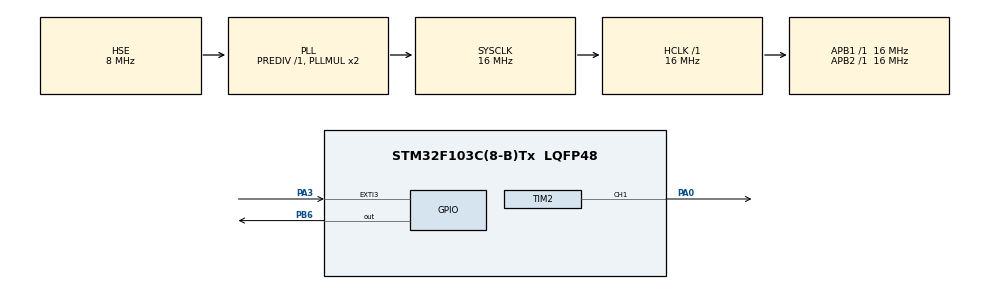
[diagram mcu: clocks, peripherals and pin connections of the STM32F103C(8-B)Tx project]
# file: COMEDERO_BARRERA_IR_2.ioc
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Mcu.Family=STM32F1
Mcu.Name=STM32F103C(8-B)Tx
Mcu.Package=LQFP48
NVIC.EXTI3_IRQn=true\:0\:0\:false\:false\:true\:true\:true\:true
NVIC.PriorityGroup=NVIC_PRIORITYGROUP_4
PA0-WKUP.Signal=S_TIM2_CH1_ETR
PA13.Mode=Serial_Wire
PA13.Signal=SYS_JTMS-SWDIO
PA14.Mode=Serial_Wire
PA14.Signal=SYS_JTCK-SWCLK
PA3.Signal=GPXTI3
PB6.Signal=GPIO_Output
PD0-OSC_IN.Mode=HSE-External-Oscillator
PD0-OSC_IN.Signal=RCC_OSC_IN
PD1-OSC_OUT.Mode=HSE-External-Oscillator
PD1-OSC_OUT.Signal=RCC_OSC_OUT
ProjectManager.HeapSize=0x200
ProjectManager.StackSize=0x400
ProjectManager.TargetToolchain=STM32CubeIDE
RCC.AHBFreq_Value=16000000
RCC.APB1Freq_Value=16000000
RCC.APB1TimFreq_Value=16000000
RCC.APB2Freq_Value=16000000
RCC.APB2TimFreq_Value=16000000
RCC.HCLKFreq_Value=16000000
RCC.PLLSourceVirtual=RCC_PLLSOURCE_HSE
RCC.SYSCLKFreq_VALUE=16000000
RCC.SYSCLKSource=RCC_SYSCLKSOURCE_PLLCLK
RCC.USBFreq_Value=16000000
SH.S_TIM2_CH1_ETR.0=TIM2_CH1,PWM Generation1 CH1
TIM2.Channel-PWM\ Generation1\ CH1=TIM_CHANNEL_1
VP_TIM2_VS_ClockSourceINT.Mode=Internal
VP_TIM3_VS_ClockSourceINT.Mode=Internal
board=custom

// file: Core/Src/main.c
/* USER CODE BEGIN Header */
/**
  ******************************************************************************
  * @file           : main.c
  * @brief          : Main program body
  ******************************************************************************
  * @attention
  *
  * Copyright (c) 2025 STMicroelectronics.
  * All rights reserved.
  *
  * This software is licensed under terms that can be found in the LICENSE file
  * in the root directory of this software component.
  * If no LICENSE file comes with this software, it is provided AS-IS.
  *
  ******************************************************************************
  */
/* USER CODE END Header */
#include "main.h"

TIM_HandleTypeDef htim2;
TIM_HandleTypeDef htim3;

/* USER CODE BEGIN PV */
volatile uint32_t ir_count = 0;
/* USER CODE END PV */

void SystemClock_Config(void);
static void MX_GPIO_Init(void);
static void MX_TIM2_Init(void);
static void MX_TIM3_Init(void);
/* USER CODE BEGIN PFP */
void delay_us(uint32_t us);
int readBarrier(unsigned int len);
/* USER CODE END PFP */

int main(void)
{

  /* MCU Configuration--------------------------------------------------------*/

  /* Reset of all peripherals, Initializes the Flash interface and the Systick. */
  HAL_Init();

  /* Configure the system clock */
  SystemClock_Config();

  /* Initialize all configured peripherals */
  MX_GPIO_Init();
  MX_TIM3_Init();
  MX_TIM2_Init();

  /* Infinite loop */
  /* USER CODE BEGIN WHILE */
  while (1)
  {
	  int c = readBarrier(10);

	  if(c > 0){
		  HAL_GPIO_WritePin(GPIOB, GPIO_PIN_6, GPIO_PIN_SET);
	  }else{
		  HAL_GPIO_WritePin(GPIOB, GPIO_PIN_6, GPIO_PIN_RESET);
	  }
    /* USER CODE END WHILE */

  }
}

void SystemClock_Config(void)
{
  RCC_OscInitTypeDef RCC_OscInitStruct = {0};
  RCC_ClkInitTypeDef RCC_ClkInitStruct = {0};

  /** Initializes the RCC Oscillators according to the specified parameters
  * in the RCC_OscInitTypeDef structure.
  */
  RCC_OscInitStruct.OscillatorType = RCC_OSCILLATORTYPE_HSE;
  RCC_OscInitStruct.HSEState = RCC_HSE_ON;
  RCC_OscInitStruct.HSEPredivValue = RCC_HSE_PREDIV_DIV1;
  RCC_OscInitStruct.HSIState = RCC_HSI_ON;
  RCC_OscInitStruct.PLL.PLLState = RCC_PLL_ON;
  RCC_OscInitStruct.PLL.PLLSource = RCC_PLLSOURCE_HSE;
  RCC_OscInitStruct.PLL.PLLMUL = RCC_PLL_MUL2;
  if (HAL_RCC_OscConfig(&RCC_OscInitStruct) != HAL_OK)
  {
    Error_Handler();
  }

  /** Initializes the CPU, AHB and APB buses clocks
  */
  RCC_ClkInitStruct.ClockType = RCC_CLOCKTYPE_HCLK|RCC_CLOCKTYPE_SYSCLK
                              |RCC_CLOCKTYPE_PCLK1|RCC_CLOCKTYPE_PCLK2;
  RCC_ClkInitStruct.SYSCLKSource = RCC_SYSCLKSOURCE_PLLCLK;
  RCC_ClkInitStruct.AHBCLKDivider = RCC_SYSCLK_DIV1;
  RCC_ClkInitStruct.APB1CLKDivider = RCC_HCLK_DIV1;
  RCC_ClkInitStruct.APB2CLKDivider = RCC_HCLK_DIV1;

  if (HAL_RCC_ClockConfig(&RCC_ClkInitStruct, FLASH_LATENCY_0) != HAL_OK)
  {
    Error_Handler();
  }
}

static void MX_TIM2_Init(void)
{

  TIM_ClockConfigTypeDef sClockSourceConfig = {0};
  TIM_MasterConfigTypeDef sMasterConfig = {0};
  TIM_OC_InitTypeDef sConfigOC = {0};

  /* USER CODE BEGIN TIM2_Init 1 */

  uint32_t pclk1 = HAL_RCC_GetPCLK1Freq();
  uint32_t timer_clk = pclk1;
  if(pclk1 != SystemCoreClock)
  {
	  timer_clk = pclk1 * 2;
  }

  const uint32_t target_freq = 38000UL;
  uint32_t period = (timer_clk / target_freq);
  if(period == 0) period = 1;
  period = period - 1;

  /* USER CODE END TIM2_Init 1 */
  htim2.Instance = TIM2;
  htim2.Init.Prescaler = 0;
  htim2.Init.CounterMode = TIM_COUNTERMODE_UP;
  htim2.Init.Period = period;
  htim2.Init.ClockDivision = TIM_CLOCKDIVISION_DIV1;
  htim2.Init.AutoReloadPreload = TIM_AUTORELOAD_PRELOAD_DISABLE;
  if (HAL_TIM_Base_Init(&htim2) != HAL_OK)
  {
    Error_Handler();
  }
  sClockSourceConfig.ClockSource = TIM_CLOCKSOURCE_INTERNAL;
  if (HAL_TIM_ConfigClockSource(&htim2, &sClockSourceConfig) != HAL_OK)
  {
    Error_Handler();
  }
  if (HAL_TIM_PWM_Init(&htim2) != HAL_OK)
  {
    Error_Handler();
  }
  sMasterConfig.MasterOutputTrigger = TIM_TRGO_RESET;
  sMasterConfig.MasterSlaveMode = TIM_MASTERSLAVEMODE_DISABLE;
  if (HAL_TIMEx_MasterConfigSynchronization(&htim2, &sMasterConfig) != HAL_OK)
  {
    Error_Handler();
  }
  sConfigOC.OCMode = TIM_OCMODE_PWM1;
  sConfigOC.Pulse = (htim2.Init.Period + 1) / 2;
  sConfigOC.OCPolarity = TIM_OCPOLARITY_HIGH;
  sConfigOC.OCFastMode = TIM_OCFAST_DISABLE;
  if (HAL_TIM_PWM_ConfigChannel(&htim2, &sConfigOC, TIM_CHANNEL_1) != HAL_OK)
  {
    Error_Handler();
  }
  /* USER CODE BEGIN TIM2_Init 2 */
  GPIO_InitTypeDef GPIO_InitStruct = {0};
  __HAL_RCC_GPIOA_CLK_ENABLE();
  GPIO_InitStruct.Pin = GPIO_PIN_0;
  GPIO_InitStruct.Mode = GPIO_MODE_AF_PP;
  GPIO_InitStruct.Speed = GPIO_SPEED_FREQ_HIGH;
  HAL_GPIO_Init(GPIOA, &GPIO_InitStruct);
  /* USER CODE END TIM2_Init 2 */
  HAL_TIM_MspPostInit(&htim2);

}

static void MX_TIM3_Init(void)
{

  TIM_ClockConfigTypeDef sClockSourceConfig = {0};
  TIM_MasterConfigTypeDef sMasterConfig = {0};

  /* USER CODE BEGIN TIM3_Init 1 */
  uint32_t pclk1 = HAL_RCC_GetPCLK1Freq();
      uint32_t tim_clk = pclk1;
      if (HAL_RCC_GetHCLKFreq() != pclk1) {
          /* If APB1 prescaler != 1 the timer clock is PCLK1 * 2 */
          tim_clk = pclk1 * 2;
      }

      uint32_t presc = (tim_clk / 1000000UL);
      if (presc == 0) presc = 1;
      presc = presc - 1; /* prescaler register = division - 1 */

  /* USER CODE END TIM3_Init 1 */
  htim3.Instance = TIM3;
  htim3.Init.Prescaler = presc;
  htim3.Init.CounterMode = TIM_COUNTERMODE_UP;
  htim3.Init.Period = 0xFFFF;
  htim3.Init.ClockDivision = TIM_CLOCKDIVISION_DIV1;
  htim3.Init.AutoReloadPreload = TIM_AUTORELOAD_PRELOAD_DISABLE;
  if (HAL_TIM_Base_Init(&htim3) != HAL_OK)
  {
    Error_Handler();
  }
  sClockSourceConfig.ClockSource = TIM_CLOCKSOURCE_INTERNAL;
  if (HAL_TIM_ConfigClockSource(&htim3, &sClockSourceConfig) != HAL_OK)
  {
    Error_Handler();
  }
  sMasterConfig.MasterOutputTrigger = TIM_TRGO_RESET;
  sMasterConfig.MasterSlaveMode = TIM_MASTERSLAVEMODE_DISABLE;
  if (HAL_TIMEx_MasterConfigSynchronization(&htim3, &sMasterConfig) != HAL_OK)
  {
    Error_Handler();
  }

}

static void MX_GPIO_Init(void)
{
  GPIO_InitTypeDef GPIO_InitStruct = {0};

  /* GPIO Ports Clock Enable */
  __HAL_RCC_GPIOD_CLK_ENABLE();
  //__HAL_RCC_GPIOA_CLK_ENABLE();
  __HAL_RCC_GPIOB_CLK_ENABLE();

  /*Configure GPIO pin Output Level */
  HAL_GPIO_WritePin(GPIOB, GPIO_PIN_6, GPIO_PIN_RESET);

  /*Configure GPIO pin : PA3 */
  GPIO_InitStruct.Pin = GPIO_PIN_3;
  GPIO_InitStruct.Mode = GPIO_MODE_IT_RISING;
  GPIO_InitStruct.Pull = GPIO_NOPULL;
  HAL_GPIO_Init(GPIOA, &GPIO_InitStruct);

  /*Configure GPIO pin : PB6 */
  GPIO_InitStruct.Pin = GPIO_PIN_6;
  GPIO_InitStruct.Mode = GPIO_MODE_OUTPUT_PP;
  GPIO_InitStruct.Pull = GPIO_NOPULL;
  GPIO_InitStruct.Speed = GPIO_SPEED_FREQ_LOW;
  HAL_GPIO_Init(GPIOB, &GPIO_InitStruct);

  /* EXTI interrupt init*/
  HAL_NVIC_SetPriority(EXTI3_IRQn, 0, 0);
  HAL_NVIC_EnableIRQ(EXTI3_IRQn);

}

/* USER CODE BEGIN 4 */

int readBarrier(unsigned int len)
{
	for(unsigned int i = 0; i < len; i ++)
	{
		HAL_TIM_PWM_Start(&htim2, TIM_CHANNEL_1);
		delay_us(600);
		HAL_TIM_PWM_Stop(&htim2, TIM_CHANNEL_1);
		delay_us(900);
	}

	uint32_t cnt = ir_count;
	ir_count = 0;
	HAL_Delay(22); // min pause.
	return (int)cnt;
}

void delay_us(uint32_t us)
{
    uint32_t start = __HAL_TIM_GET_COUNTER(&htim3);
    /* if timer stopped / not running, avoid infinite loop */
    uint32_t timeout = us + 1000;
    while ((__HAL_TIM_GET_COUNTER(&htim3) - start) < us)
    {
        if (--timeout == 0) break;
    }
}

void HAL_GPIO_EXTI_Callback(uint16_t GPIO_Pin) {
    if (GPIO_Pin == GPIO_PIN_3) {
        ir_count++;
    }
}

/* USER CODE END 4 */

void Error_Handler(void)
{
  __disable_irq();
  while (1)
  {
  }
}
